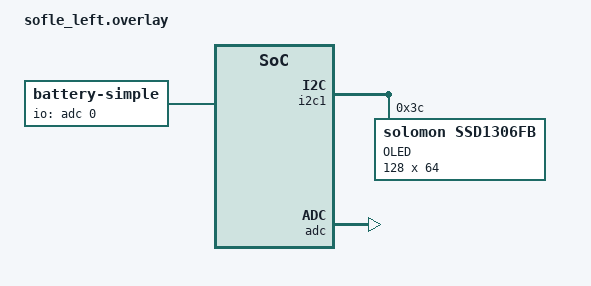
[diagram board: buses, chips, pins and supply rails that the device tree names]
/ {
  chosen {
    zmk,kscan = &kscan0;
    zmk,display = &oled;
  };
};

&i2c1 {
  status = "okay";

  oled: oled@3c {
    compatible = "solomon,ssd1306fb";
    reg = <0x3c>;
    label = "OLED";
    width = <128>;
    height = <64>;
  };
};

&adc {
  status = "okay";
};

&zephyr_udc0 {
  battery {
    compatible = "zmk,battery-simple";
    io-channels = <&adc 0>;
    label = "BAT";
  };
};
